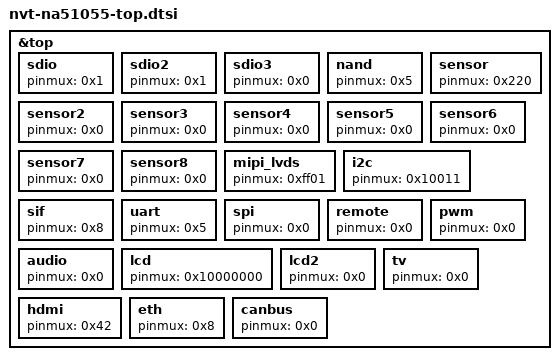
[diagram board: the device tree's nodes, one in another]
&top {
	sdio{pinmux = <0x1>;};
	sdio2{pinmux = <0x1>;};
	sdio3{pinmux = <0x0>;};
	nand{pinmux = <0x5>;};
	sensor{pinmux = <0x220>;};
	sensor2{pinmux = <0x0>;};
	sensor3{pinmux = <0x0>;};
	sensor4{pinmux = <0x0>;};
	sensor5{pinmux = <0x0>;};
	sensor6{pinmux = <0x0>;};
	sensor7{pinmux = <0x0>;};
	sensor8{pinmux = <0x0>;};
	mipi_lvds{pinmux = <0xff01>;};
	i2c{pinmux = <0x10011>;};
	sif{pinmux = <0x8>;};
	uart{pinmux = <0x5>;};
	spi{pinmux = <0x0>;};
	remote{pinmux = <0x0>;};
	pwm{pinmux = <0x0>;};
	audio{pinmux = <0x0>;};
	lcd{pinmux = <0x10000000>;};
	lcd2{pinmux = <0x0>;};
	tv{pinmux = <0x0>;};
	hdmi{pinmux = <0x42>;};
	eth{pinmux = <0x8>;};
	canbus{pinmux = <0x0>;};
};
